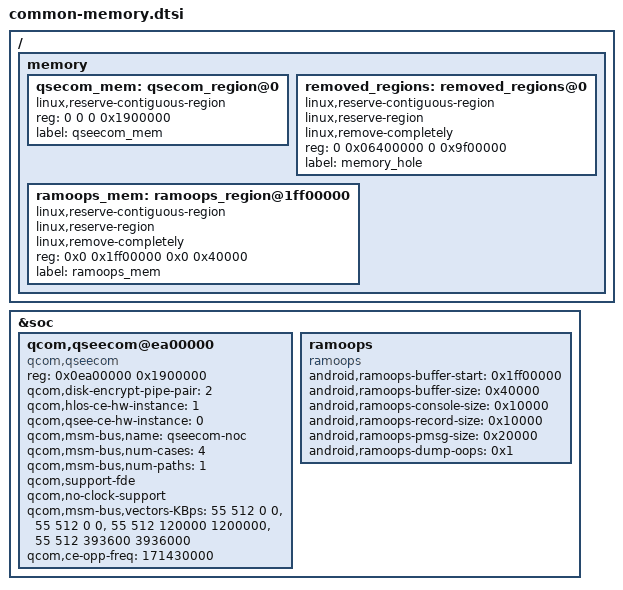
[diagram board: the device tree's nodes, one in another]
/* Copyright (c) 2017, The Linux Foundation. All rights reserved.
 *
 * This program is free software; you can redistribute it and/or modify
 * it under the terms of the GNU General Public License version 2 and
 * only version 2 as published by the Free Software Foundation.
 *
 * This program is distributed in the hope that it will be useful,
 * but WITHOUT ANY WARRANTY; without even the implied warranty of
 * MERCHANTABILITY or FITNESS FOR A PARTICULAR PURPOSE.  See the
 * GNU General Public License for more details.
 */

/ {
	memory {
		qsecom_mem: qsecom_region@0 {
			linux,reserve-contiguous-region;
			reg = <0 0 0 0x1900000>;
			label = "qseecom_mem";
		};

		removed_regions: removed_regions@0 {
			linux,reserve-contiguous-region;
			linux,reserve-region;
			linux,remove-completely;
			reg = <0 0x06400000 0 0x9f00000>;
			label = "memory_hole";
		};

		ramoops_mem: ramoops_region@1ff00000 {
			linux,reserve-contiguous-region;
			linux,reserve-region;
			linux,remove-completely;
			reg = <0x0 0x1ff00000 0x0 0x40000>;
			label = "ramoops_mem";
		};
	};
};

&soc {
	/delete-node/ qcom,qseecom@6500000;
	qcom,qseecom@ea00000 {
		compatible = "qcom,qseecom";
		reg = <0x0ea00000 0x1900000>;
		reg-names = "secapp-region";
		qcom,disk-encrypt-pipe-pair = <2>;
		qcom,hlos-ce-hw-instance = <1>;
		qcom,qsee-ce-hw-instance = <0>;
		qcom,msm-bus,name = "qseecom-noc";
		qcom,msm-bus,num-cases = <4>;
		qcom,msm-bus,num-paths = <1>;
		qcom,support-fde;
		qcom,no-clock-support;
		qcom,msm-bus,vectors-KBps =
				<55 512 0 0>,
				<55 512 0 0>,
				<55 512 120000 1200000>,
				<55 512 393600 3936000>;
		qcom,ce-opp-freq = <171430000>;
	};

	ramoops {
		compatible = "ramoops";
		status = "okay";

		android,ramoops-buffer-start = <0x1ff00000>;
		android,ramoops-buffer-size =  <0x40000>;
		android,ramoops-console-size = <0x10000>;
		android,ramoops-record-size = <0x10000>;
		android,ramoops-pmsg-size = <0x20000>;
		android,ramoops-dump-oops = <0x1>;
	};
};
